# tviic2d6m register map
Vendor: Infineon Technologies; Series: TVIIC2D6M; File version: 1.0
CPU: CM7 r0p1, little endian, MPU, FPU, double-precision FPU, I-cache, D-cache, VTOR, ITCM, DTCM, 3 interrupt priority bits, 16 interrupts
Registers are 32-bit, read-write, reset 0x0 unless marked. A register's access mark holds for its fields unless they carry their own. Offsets are from the block's base; [hi:lo] are bit positions; lines under a group give offsets from that group; {n}, {i} and the like mark numbered series.

## PERI_PCLK — Peripheral PCLK groups
Base 0x40040000
{0x0+0x2000*i} GR[{i}] (i=0..1) group — PERI clock domains
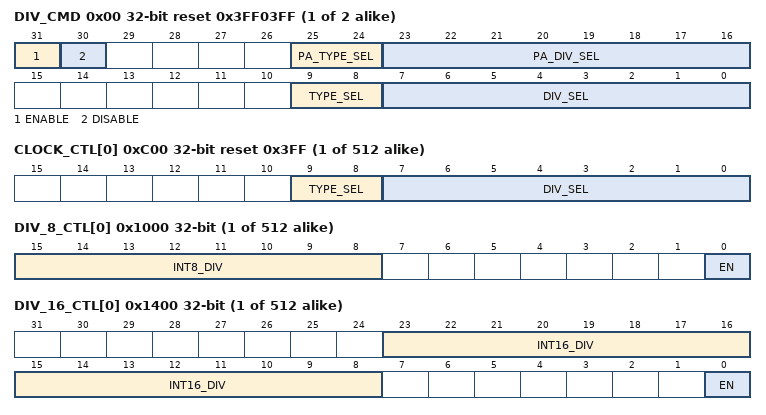
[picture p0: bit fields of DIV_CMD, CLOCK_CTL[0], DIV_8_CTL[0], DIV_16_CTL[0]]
  0x00 DIV_CMD reset 0x3FF03FF — Divider command
    [31] ENABLE — Clock divider enable command (mutually exclusive with DISABLE). Typically, SW sets this field to '1' to enable a divider and HW sets this field to '0' to indicate that divider enabling has completed. When a divider is enabled, its integer and fractional (if present) counters are initialized to '0'. If a divider is to be re-enabled using different integer and fractional divider values, the SW should follow these steps: 0: Disable the divider using the DIV_CMD.DISABLE field. 1: Configure the divider's DIV_XXX_CTL register. 2: Enable the divider using the DIV_CMD_ENABLE field. The DIV_SEL and TYPE_SEL fields specify which divider is to be enabled. The enabled divider may be phase aligned to either 'clk_pclk_root[i]' (typical usage) or to ANY enabled divider. The PA_DIV_SEL and PA_TYPE_SEL fields specify the reference divider. The HW sets the ENABLE field to '0' when the enabling is performed and the HW set the DIV_XXX_CTL.EN field of the divider to '1' when the enabling is performed. Note that enabling with phase alignment to a low frequency divider takes time. E.g. To align to a divider that generates a clock of 'clk_pclk_root[i]'/n (with n being the integer divider value INT_DIV+1), up to n cycles may be required to perform alignment. Phase alignment to 'clk_pclk_root[i]' takes affect immediately. SW can set this field to '0' during phase alignment to abort the enabling process.
    [30] DISABLE — Clock divider disable command (mutually exclusive with ENABLE). SW sets this field to '1' and HW sets this field to '0'. The DIV_SEL and TYPE_SEL fields specify which divider is to be disabled. The HW sets the DISABLE field to '0' immediately and the HW sets the DIV_XXX_CTL.EN field of the divider to '0' immediately.
    [25:24] PA_TYPE_SEL — Specifies the divider type of the divider to which phase alignment is performed for the clock enable command: 0: 8.0 (integer) clock dividers. 1: 16.0 (integer) clock dividers. 2: 16.5 (fractional) clock dividers. 3: 24.5 (fractional) clock dividers.
    [23:16] PA_DIV_SEL — (PA_TYPE_SEL, PA_DIV_SEL) specifies the divider to which phase alignment is performed for the clock enable command. Any enabled divider can be used as reference. This allows all dividers to be aligned with each other, even when they are enabled at different times. If PA_DIV_SEL is '255' and PA_TYPE_SEL is '3', 'clk_pclk_root[i]' is used as reference.
    [9:8] TYPE_SEL — Specifies the divider type of the divider on which the command is performed: 0: 8.0 (integer) clock dividers. 1: 16.0 (integer) clock dividers. 2: 16.5 (fractional) clock dividers. 3: 24.5 (fractional) clock dividers.
    [7:0] DIV_SEL — (TYPE_SEL, DIV_SEL) specifies the divider on which the command (DISABLE/ENABLE) is performed. If DIV_SEL is '255' and TYPE_SEL is '3' (default/reset value), no divider is specified and no clock signal(s) are generated.
  {0xC00+4j} CLOCK_CTL[{j}] (j=0..255) reset 0x3FF — Clock control
    [9:8] TYPE_SEL — Specifies divider type: 0: 8.0 (integer) clock dividers. 1: 16.0 (integer) clock dividers. 2: 16.5 (fractional) clock dividers. 3: 24.5 (fractional) clock dividers.
    [7:0] DIV_SEL — Specifies one of the dividers of the divider type specified by TYPE_SEL. If DIV_SEL is '255' and TYPE_SEL is '3' (default/reset value), no divider is specified and no clock control signal(s) are generated. When transitioning a clock between two out-of-phase dividers, spurious clock control signals may be generated for one 'clk_pclk_root[i]' cycle during this transition. These clock control signals may cause a single clock period that is smaller than any of the two divider periods. To prevent these spurious clock signals, the clock multiplexer can be disconnected (DIV_SEL is '255' and TYPE_SEL is '3') for a transition time that is larger than the smaller of the two divider periods.
  {0x1000+4j} DIV_8_CTL[{j}] (j=0..255) — Divider control (for 8.0 divider)
    [15:8] INT8_DIV — Integer division by (1+INT8_DIV). Allows for integer divisions in the range [1, 256]. Note: this type of divider does NOT allow for a fractional division. For the generation of a divided clock, the integer division range is restricted to [2, 256]. For the generation of a 50/50 percent duty cycle digital divided clock, the integer division range is restricted to even numbers in the range [2, 256]. The generation of a 50/50 percent duty cycle analog divided clock has no restrictions. Note that this field is retained. However, the counter that is used to implement the division is not and will be initialized by HW to '0' when transitioning from DeepSleep to Active power mode.
    [0] EN ro — Divider enabled. HW sets this field to '1' as a result of an ENABLE command. HW sets this field to '0' as a result on a DISABLE command. Note that this field is retained. As a result, the divider does NOT have to be re-enabled after transitioning from DeepSleep to Active power mode.
  {0x1400+4j} DIV_16_CTL[{j}] (j=0..255) — Divider control (for 16.0 divider)
    [23:8] INT16_DIV — Integer division by (1+INT16_DIV). Allows for integer divisions in the range [1, 65,536]. Note: this type of divider does NOT allow for a fractional division. For the generation of a divided clock, the integer division range is restricted to [2, 65,536]. For the generation of a 50/50 percent duty cycle digital divided clock, the integer division range is restricted to even numbers in the range [2, 65,536]. The generation of a 50/50 percent duty cycle analog divided clock has no restrictions. Note that this field is retained. However, the counter that is used to implement the division is not and will be initialized by HW to '0' when transitioning from DeepSleep to Active power mode.
    [0] EN ro — Divider enabled. HW sets this field to '1' as a result of an ENABLE command. HW sets this field to '0' as a result on a DISABLE command. Note that this field is retained. As a result, the divider does NOT have to be re-enabled after transitioning from DeepSleep to Active power mode.
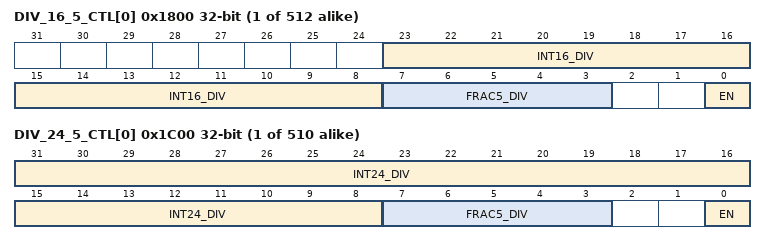
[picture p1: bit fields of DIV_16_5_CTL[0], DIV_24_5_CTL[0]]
  {0x1800+4j} DIV_16_5_CTL[{j}] (j=0..255) — Divider control (for 16.5 divider)
    [23:8] INT16_DIV — Integer division by (1+INT16_DIV). Allows for integer divisions in the range [1, 65,536]. Note: combined with fractional division, this divider type allows for a division in the range [1, 65,536 31/32] in 1/32 increments. For the generation of a divided clock, the division range is restricted to [2, 65,536 31/32]. For the generation of a 50/50 percent duty cycle divided clock, the division range is restricted to [2, 65,536]. Note that this field is retained. However, the counter that is used to implement the division is not and will be initialized by HW to '0' when transitioning from DeepSleep to Active power mode.
    [7:3] FRAC5_DIV — Fractional division by (FRAC5_DIV/32). Allows for fractional divisions in the range [0, 31/32]. Note that fractional division results in clock jitter as some clock periods may be 1 'clk_pclk_root[i]' cycle longer than other clock periods. Note that this field is retained. However, the counter that is used to implement the division is not and will be initialized by HW to '0' when transitioning from DeepSleep to Active power mode.
    [0] EN ro — Divider enabled. HW sets this field to '1' as a result of an ENABLE command. HW sets this field to '0' as a result on a DISABLE command. Note that this field is retained. As a result, the divider does NOT have to be re-enabled after transitioning from DeepSleep to Active power mode.
  {0x1C00+4j} DIV_24_5_CTL[{j}] (j=0..254) — Divider control (for 24.5 divider)
    [31:8] INT24_DIV — Integer division by (1+INT24_DIV). Allows for integer divisions in the range [1, 16,777,216]. Note: combined with fractional division, this divider type allows for a division in the range [1, 16,777,216 31/32] in 1/32 increments. For the generation of a divided clock, the integer division range is restricted to [2, 16,777,216 31/32]. For the generation of a 50/50 percent duty cycle divided clock, the division range is restricted to [2, 16,777,216]. Note that this field is retained. However, the counter that is used to implement the division is not and will be initialized by HW to '0' when transitioning from DeepSleep to Active power mode.
    [7:3] FRAC5_DIV — Fractional division by (FRAC5_DIV/32). Allows for fractional divisions in the range [0, 31/32]. Note that fractional division results in clock jitter as some clock periods may be 1 'clk_pclk_root[i]' cycle longer than other clock periods. Note that this field is retained. However, the counter that is used to implement the division is not and will be initialized by HW to '0' when transitioning from DeepSleep to Active power mode.
    [0] EN ro — Divider enabled. HW sets this field to '1' as a result of an ENABLE command. HW sets this field to '0' as a result on a DISABLE command. Note that this field is retained. As a result, the divider does NOT have to be re-enabled after transitioning from DeepSleep to Active power mode.
